AUTOSAR XML (schema 00046)
package /ComponentTypes
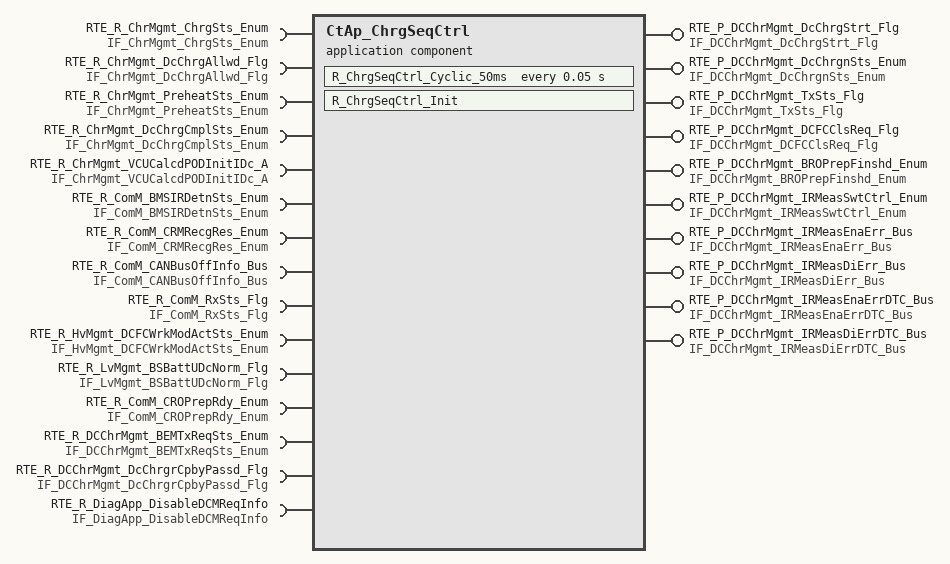
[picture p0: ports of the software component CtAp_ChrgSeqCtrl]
  application sw component type CtAp_ChrgSeqCtrl
    10 x provide port:
      RTE_P_DCChrMgmt_DcChrgStrt_Flg: nonqueued-sender-com-spec{data-element=tec_DCChrMgmt_DcChrgStrt_Flg, init-value=0}, provided-interface=IF_DCChrMgmt_DcChrgStrt_Flg
      RTE_P_DCChrMgmt_DcChrgnSts_Enum: nonqueued-sender-com-spec{data-element=tec_DCChrMgmt_DcChrgnSts_Enum, init-value=0}, provided-interface=IF_DCChrMgmt_DcChrgnSts_Enum
      RTE_P_DCChrMgmt_TxSts_Flg: provided-interface=IF_DCChrMgmt_TxSts_Flg
        provided-com-specs:
          data-element=tec_DCChrMgmt_TxBSDSts_Flg, init-value=0
          data-element=tec_DCChrMgmt_TxBEMSts_Flg, init-value=0
          data-element=tec_DCChrMgmt_TxBSMSts_Flg, init-value=0
          data-element=tec_DCChrMgmt_TxBCSSts_Flg, init-value=0
          data-element=tec_DCChrMgmt_TxBSTSts_Flg, init-value=0
          data-element=tec_DCChrMgmt_TxBCLSts_Flg, init-value=0
          data-element=tec_DCChrMgmt_TxBROSts_Flg, init-value=0
          data-element=tec_DCChrMgmt_TxBCPSts_Flg, init-value=0
          data-element=tec_DCChrMgmt_TxBRMSts_Flg, init-value=0
          data-element=tec_DCChrMgmt_TxBHMSts_Flg, init-value=0
      RTE_P_DCChrMgmt_DCFCClsReq_Flg: nonqueued-sender-com-spec{data-element=tec_DCChrMgmt_DCFCClsReq_Flg, init-value=0}, provided-interface=IF_DCChrMgmt_DCFCClsReq_Flg
      RTE_P_DCChrMgmt_BROPrepFinshd_Enum: nonqueued-sender-com-spec{data-element=tec_DCChrMgmt_BROPrepFinshd_Enum, init-value=0}, provided-interface=IF_DCChrMgmt_BROPrepFinshd_Enum
      RTE_P_DCChrMgmt_IRMeasSwtCtrl_Enum: nonqueued-sender-com-spec{data-element=tec_DCChrMgmt_IRMeasSwtCtrl_Enum, init-value=0}, provided-interface=IF_DCChrMgmt_IRMeasSwtCtrl_Enum
      RTE_P_DCChrMgmt_IRMeasEnaErr_Bus: nonqueued-sender-com-spec{data-element=tec_DCChrMgmt_IRMeasEnaErr_Bus, init-value=fields=[DCChrMgmt_MonStatIRMeasEnaErr:0, DCChrMgmt_MonResIRMeasEnaErr:0, DCChrMgmt_ErrStatIRMeasEnaErr:0, DCChrMgmt_ErrResIRMeasEnaErr:0]}, provided-interface=IF_DCChrMgmt_IRMeasEnaErr_Bus
      RTE_P_DCChrMgmt_IRMeasDiErr_Bus: nonqueued-sender-com-spec{data-element=tec_DCChrMgmt_IRMeasDiErr_Bus, init-value=fields=[DCChrMgmt_MonStatIRMeasDiErr:0, DCChrMgmt_MonResIRMeasDiErr:0, DCChrMgmt_ErrStatIRMeasDiErr:0, DCChrMgmt_ErrResIRMeasDiErr:0]}, provided-interface=IF_DCChrMgmt_IRMeasDiErr_Bus
      RTE_P_DCChrMgmt_IRMeasEnaErrDTC_Bus: nonqueued-sender-com-spec{data-element=tec_DCChrMgmt_IRMeasEnaErrDTC_Bus, init-value=fields=[DCChrMgmt_MonStatIRMeasEnaErrDTC:0, DCChrMgmt_MonResIRMeasEnaErrDTC:0, DCChrMgmt_ErrStatIRMeasEnaErrDTC:0, DCChrMgmt_ErrResIRMeasEnaErrDTC:0]}, provided-interface=IF_DCChrMgmt_IRMeasEnaErrDTC_Bus
      RTE_P_DCChrMgmt_IRMeasDiErrDTC_Bus: nonqueued-sender-com-spec{data-element=tec_DCChrMgmt_IRMeasDiErrDTC_Bus, init-value=fields=[DCChrMgmt_MonStatIRMeasDiErrDTC:0, DCChrMgmt_MonResIRMeasDiErrDTC:0, DCChrMgmt_ErrStatIRMeasDiErrDTC:0, DCChrMgmt_ErrResIRMeasDiErrDTC:0]}, provided-interface=IF_DCChrMgmt_IRMeasDiErrDTC_Bus
    15 x require port:
      RTE_R_ChrMgmt_ChrgSts_Enum: nonqueued-receiver-com-spec{data-element=tec_ChrMgmt_ChrgSts_Enum, filter=data-filter-type=ALWAYS, init-value=0}, required-interface=IF_ChrMgmt_ChrgSts_Enum
      RTE_R_ChrMgmt_DcChrgAllwd_Flg: nonqueued-receiver-com-spec{data-element=tec_ChrMgmt_DcChrgAllwd_Flg, filter=data-filter-type=ALWAYS, init-value=0}, required-interface=IF_ChrMgmt_DcChrgAllwd_Flg
      RTE_R_ChrMgmt_PreheatSts_Enum: nonqueued-receiver-com-spec{data-element=tec_ChrMgmt_PreheatSts_Enum, filter=data-filter-type=ALWAYS, init-value=0}, required-interface=IF_ChrMgmt_PreheatSts_Enum
      RTE_R_ChrMgmt_DcChrgCmplSts_Enum: nonqueued-receiver-com-spec{data-element=tec_ChrMgmt_DcChrgCmplSts_Enum, filter=data-filter-type=ALWAYS, init-value=0}, required-interface=IF_ChrMgmt_DcChrgCmplSts_Enum
      RTE_R_ChrMgmt_VCUCalcdPODInitIDc_A: nonqueued-receiver-com-spec{data-element=tec_ChrMgmt_VCUCalcdPODInitIDc_A, filter=data-filter-type=ALWAYS, init-value=0}, required-interface=IF_ChrMgmt_VCUCalcdPODInitIDc_A
      RTE_R_ComM_BMSIRDetnSts_Enum: nonqueued-receiver-com-spec{data-element=tec_ComM_BMSIRDetnSts_Enum, filter=data-filter-type=ALWAYS, init-value=0}, required-interface=IF_ComM_BMSIRDetnSts_Enum
      RTE_R_ComM_CRMRecgRes_Enum: nonqueued-receiver-com-spec{data-element=tec_ComM_CRMRecgRes_Enum, filter=data-filter-type=ALWAYS, init-value=0}, required-interface=IF_ComM_CRMRecgRes_Enum
      RTE_R_ComM_CANBusOffInfo_Bus: required-interface=IF_ComM_CANBusOffInfo_Bus
        required-com-specs:
          data-element=tec_ComM_EPTCANBusOffInfo_Bus, filter=data-filter-type=ALWAYS, init-value=fields=[ComM_MonStatEPTCANBusOffInfo:0, ComM_MonResEPTCANBusOffInfo:0, ComM_ErrStatEPTCANBusOffInfo:0, ComM_ErrResEPTCANBusOffInfo:0]
          data-element=tec_ComM_CHCANBusOffInfo_Bus, filter=data-filter-type=ALWAYS, init-value=fields=[ComM_MonStatCHCANBusOffInfo:0, ComM_MonResCHCANBusOffInfo:0, ComM_ErrStatCHCANBusOffInfo:0, ComM_ErrResCHCANBusOffInfo:0]
          data-element=tec_ComM_EPTCANBusOffDTCInfo_Bus, filter=data-filter-type=ALWAYS, init-value=fields=[ComM_MonStatEPTCANBusOffDTCInfo:0, ComM_MonResEPTCANBusOffDTCInfo:0, ComM_ErrStatEPTCANBusOffDTCInfo:0, ComM_ErrResEPTCANBusOffDTCInfo:0]
          data-element=tec_ComM_CHCANBusOffDTCInfo_Bus, filter=data-filter-type=ALWAYS, init-value=fields=[ComM_MonStatCHCANBusOffDTCInfo:0, ComM_MonResCHCANBusOffDTCInfo:0, ComM_ErrStatCHCANBusOffDTCInfo:0, ComM_ErrResCHCANBusOffDTCInfo:0]
          data-element=tec_ComM_DCCANBusOffDTCInfo_Bus, init-value=fields=[ComM_MonStatDCCANDTCBusOffInfo:0, ComM_MonResDCCANDTCBusOffInfo:0, ComM_ErrStatDCCANDTCBusOffInfo:0, ComM_ErrResDCCANDTCBusOffInfo:0]
          data-element=tec_ComM_DCCANBusOffInfo_Bus, init-value=fields=[ComM_MonStatDCCANBusOffInfo:0, ComM_MonResDCCANBusOffInfo:0, ComM_ErrStatDCCANBusOffInfo:0, ComM_ErrResDCCANBusOffInfo:0]
      RTE_R_ComM_RxSts_Flg: required-interface=IF_ComM_RxSts_Flg
        required-com-specs:
          data-element=tec_ComM_RxCROSts_Flg, filter=data-filter-type=ALWAYS, init-value=0
          data-element=tec_ComM_RxCEMSts_Flg, filter=data-filter-type=ALWAYS, init-value=0
          data-element=tec_ComM_RxCHMSts_Flg, filter=data-filter-type=ALWAYS, init-value=0
          data-element=tec_ComM_RxCSTSts_Flg, filter=data-filter-type=ALWAYS, init-value=0
          data-element=tec_ComM_RxCSDSts_Flg, filter=data-filter-type=ALWAYS, init-value=0
          data-element=tec_ComM_RxCCSSts_Flg, filter=data-filter-type=ALWAYS, init-value=0
          data-element=tec_ComM_RxCMLSts_Flg, filter=data-filter-type=ALWAYS, init-value=0
          data-element=tec_ComM_RxCRMSts_Flg, filter=data-filter-type=ALWAYS, init-value=0
      RTE_R_HvMgmt_DCFCWrkModActSts_Enum: nonqueued-receiver-com-spec{data-element=tec_HvMgmt_DCFCWrkModActSts_Enum, filter=data-filter-type=ALWAYS, init-value=0}, required-interface=IF_HvMgmt_DCFCWrkModActSts_Enum
      RTE_R_LvMgmt_BSBattUDcNorm_Flg: nonqueued-receiver-com-spec{data-element=tec_LvMgmt_BSBattUDcNorm_Flg, filter=data-filter-type=ALWAYS, init-value=0}, required-interface=IF_LvMgmt_BSBattUDcNorm_Flg
      RTE_R_ComM_CROPrepRdy_Enum: nonqueued-receiver-com-spec{data-element=tec_ComM_CROPrepRdy_Enum, filter=data-filter-type=ALWAYS, init-value=0}, required-interface=IF_ComM_CROPrepRdy_Enum
      RTE_R_DCChrMgmt_BEMTxReqSts_Enum: nonqueued-receiver-com-spec{data-element=tec_DCChrMgmt_BEMTxReqSts_Enum, filter=data-filter-type=ALWAYS, init-value=0}, required-interface=IF_DCChrMgmt_BEMTxReqSts_Enum
      RTE_R_DCChrMgmt_DcChrgrCpbyPassd_Flg: nonqueued-receiver-com-spec{data-element=tec_DCChrMgmt_DcChrgrCpbyPassd_Flg, filter=data-filter-type=ALWAYS, init-value=0}, required-interface=IF_DCChrMgmt_DcChrgrCpbyPassd_Flg
      RTE_R_DiagApp_DisableDCMReqInfo: nonqueued-receiver-com-spec{data-element=tec_DiagApp_DisableDCMReqInfo, filter=data-filter-type=ALWAYS, init-value=0}, required-interface=IF_DiagApp_DisableDCMReqInfo
    behavior CtAp_ChrgSeqCtrl_InternalBehavior
      timing event TMT_R_ChrgSeqCtrl_Cyclic_50ms: start-on-event=R_ChrgSeqCtrl_Cyclic_50ms, period=0.05
      init event CtAp_ChrgSeqCtrl_InitEvent: start-on-event=R_ChrgSeqCtrl_Init
      runnable R_ChrgSeqCtrl_Cyclic_50ms
        data-receive-point-by-arguments:
          22 x access:
            REC_RTE_R_ChrMgmt_ChrgSts_Enum_tec_ChrMgmt_ChrgSts_Enum: accessed-variable=RTE_R_ChrMgmt_ChrgSts_Enum.tec_ChrMgmt_ChrgSts_Enum
            REC_RTE_R_ChrMgmt_DcChrgAllwd_Flg_tec_ChrMgmt_DcChrgAllwd_Flg: accessed-variable=RTE_R_ChrMgmt_DcChrgAllwd_Flg.tec_ChrMgmt_DcChrgAllwd_Flg
            REC_RTE_R_ChrMgmt_DcChrgCmplSts_Enum_tec_ChrMgmt_DcChrgCmplSts_Enum: accessed-variable=RTE_R_ChrMgmt_DcChrgCmplSts_Enum.tec_ChrMgmt_DcChrgCmplSts_Enum
            REC_RTE_R_ChrMgmt_PreheatSts_Enum_tec_ChrMgmt_PreheatSts_Enum: accessed-variable=RTE_R_ChrMgmt_PreheatSts_Enum.tec_ChrMgmt_PreheatSts_Enum
            REC_RTE_R_ChrMgmt_VCUCalcdPODInitIDc_A_tec_ChrMgmt_VCUCalcdPODInitIDc_A: accessed-variable=RTE_R_ChrMgmt_VCUCalcdPODInitIDc_A.tec_ChrMgmt_VCUCalcdPODInitIDc_A
            REC_RTE_R_ComM_BMSIRDetnSts_Enum_tec_ComM_BMSIRDetnSts_Enum: accessed-variable=RTE_R_ComM_BMSIRDetnSts_Enum.tec_ComM_BMSIRDetnSts_Enum
            REC_RTE_R_ComM_CANBusOffInfo_Bus_tec_ComM_EPTCANBusOffInfo_Bus: accessed-variable=RTE_R_ComM_CANBusOffInfo_Bus.tec_ComM_EPTCANBusOffInfo_Bus
            REC_RTE_R_ComM_CRMRecgRes_Enum_tec_ComM_CRMRecgRes_Enum: accessed-variable=RTE_R_ComM_CRMRecgRes_Enum.tec_ComM_CRMRecgRes_Enum
            REC_RTE_R_ComM_CROPrepRdy_Enum_tec_ComM_CROPrepRdy_Enum: accessed-variable=RTE_R_ComM_CROPrepRdy_Enum.tec_ComM_CROPrepRdy_Enum
            REC_RTE_R_ComM_RxSts_Flg_tec_ComM_RxCCSSts_Flg: accessed-variable=RTE_R_ComM_RxSts_Flg.tec_ComM_RxCCSSts_Flg
            REC_RTE_R_ComM_RxSts_Flg_tec_ComM_RxCEMSts_Flg: accessed-variable=RTE_R_ComM_RxSts_Flg.tec_ComM_RxCEMSts_Flg
            REC_RTE_R_ComM_RxSts_Flg_tec_ComM_RxCHMSts_Flg: accessed-variable=RTE_R_ComM_RxSts_Flg.tec_ComM_RxCHMSts_Flg
            REC_RTE_R_ComM_RxSts_Flg_tec_ComM_RxCMLSts_Flg: accessed-variable=RTE_R_ComM_RxSts_Flg.tec_ComM_RxCMLSts_Flg
            REC_RTE_R_ComM_RxSts_Flg_tec_ComM_RxCRMSts_Flg: accessed-variable=RTE_R_ComM_RxSts_Flg.tec_ComM_RxCRMSts_Flg
            REC_RTE_R_ComM_RxSts_Flg_tec_ComM_RxCROSts_Flg: accessed-variable=RTE_R_ComM_RxSts_Flg.tec_ComM_RxCROSts_Flg
            REC_RTE_R_ComM_RxSts_Flg_tec_ComM_RxCSDSts_Flg: accessed-variable=RTE_R_ComM_RxSts_Flg.tec_ComM_RxCSDSts_Flg
            REC_RTE_R_ComM_RxSts_Flg_tec_ComM_RxCSTSts_Flg: accessed-variable=RTE_R_ComM_RxSts_Flg.tec_ComM_RxCSTSts_Flg
            REC_RTE_R_DCChrMgmt_BEMTxReqSts_Enum_tec_DCChrMgmt_BEMTxReqSts_Enum: accessed-variable=RTE_R_DCChrMgmt_BEMTxReqSts_Enum.tec_DCChrMgmt_BEMTxReqSts_Enum
            REC_RTE_R_DCChrMgmt_DcChrgrCpbyPassd_Flg_tec_DCChrMgmt_DcChrgrCpbyPassd_Flg: accessed-variable=RTE_R_DCChrMgmt_DcChrgrCpbyPassd_Flg.tec_DCChrMgmt_DcChrgrCpbyPassd_Flg
            REC_RTE_R_HvMgmt_DCFCWrkModActSts_Enum_tec_HvMgmt_DCFCWrkModActSts_Enum: accessed-variable=RTE_R_HvMgmt_DCFCWrkModActSts_Enum.tec_HvMgmt_DCFCWrkModActSts_Enum
            REC_RTE_R_LvMgmt_BSBattUDcNorm_Flg_tec_LvMgmt_BSBattUDcNorm_Flg: accessed-variable=RTE_R_LvMgmt_BSBattUDcNorm_Flg.tec_LvMgmt_BSBattUDcNorm_Flg
            REC_RTE_R_DiagApp_DisableDCMReqInfo_tec_DiagApp_DisableDCMReqInfo: accessed-variable=RTE_R_DiagApp_DisableDCMReqInfo.tec_DiagApp_DisableDCMReqInfo
        data-send-points:
          19 x access:
            SEND_RTE_P_DCChrMgmt_BROPrepFinshd_Enum_tec_DCChrMgmt_BROPrepFinshd_Enum: accessed-variable=RTE_P_DCChrMgmt_BROPrepFinshd_Enum.tec_DCChrMgmt_BROPrepFinshd_Enum
            SEND_RTE_P_DCChrMgmt_DCFCClsReq_Flg_tec_DCChrMgmt_DCFCClsReq_Flg: accessed-variable=RTE_P_DCChrMgmt_DCFCClsReq_Flg.tec_DCChrMgmt_DCFCClsReq_Flg
            SEND_RTE_P_DCChrMgmt_DcChrgStrt_Flg_tec_DCChrMgmt_DcChrgStrt_Flg: accessed-variable=RTE_P_DCChrMgmt_DcChrgStrt_Flg.tec_DCChrMgmt_DcChrgStrt_Flg
            SEND_RTE_P_DCChrMgmt_DcChrgnSts_Enum_tec_DCChrMgmt_DcChrgnSts_Enum: accessed-variable=RTE_P_DCChrMgmt_DcChrgnSts_Enum.tec_DCChrMgmt_DcChrgnSts_Enum
            SEND_RTE_P_DCChrMgmt_IRMeasDiErrDTC_Bus_tec_DCChrMgmt_IRMeasDiErrDTC_Bus: accessed-variable=RTE_P_DCChrMgmt_IRMeasDiErrDTC_Bus.tec_DCChrMgmt_IRMeasDiErrDTC_Bus
            SEND_RTE_P_DCChrMgmt_IRMeasDiErr_Bus_tec_DCChrMgmt_IRMeasDiErr_Bus: accessed-variable=RTE_P_DCChrMgmt_IRMeasDiErr_Bus.tec_DCChrMgmt_IRMeasDiErr_Bus
            SEND_RTE_P_DCChrMgmt_IRMeasEnaErrDTC_Bus_tec_DCChrMgmt_IRMeasEnaErrDTC_Bus: accessed-variable=RTE_P_DCChrMgmt_IRMeasEnaErrDTC_Bus.tec_DCChrMgmt_IRMeasEnaErrDTC_Bus
            SEND_RTE_P_DCChrMgmt_IRMeasEnaErr_Bus_tec_DCChrMgmt_IRMeasEnaErr_Bus: accessed-variable=RTE_P_DCChrMgmt_IRMeasEnaErr_Bus.tec_DCChrMgmt_IRMeasEnaErr_Bus
            SEND_RTE_P_DCChrMgmt_IRMeasSwtCtrl_Enum_tec_DCChrMgmt_IRMeasSwtCtrl_Enum: accessed-variable=RTE_P_DCChrMgmt_IRMeasSwtCtrl_Enum.tec_DCChrMgmt_IRMeasSwtCtrl_Enum
            SEND_RTE_P_DCChrMgmt_TxSts_Flg_tec_DCChrMgmt_TxBCLSts_Flg: accessed-variable=RTE_P_DCChrMgmt_TxSts_Flg.tec_DCChrMgmt_TxBCLSts_Flg
            SEND_RTE_P_DCChrMgmt_TxSts_Flg_tec_DCChrMgmt_TxBCPSts_Flg: accessed-variable=RTE_P_DCChrMgmt_TxSts_Flg.tec_DCChrMgmt_TxBCPSts_Flg
            SEND_RTE_P_DCChrMgmt_TxSts_Flg_tec_DCChrMgmt_TxBCSSts_Flg: accessed-variable=RTE_P_DCChrMgmt_TxSts_Flg.tec_DCChrMgmt_TxBCSSts_Flg
            SEND_RTE_P_DCChrMgmt_TxSts_Flg_tec_DCChrMgmt_TxBEMSts_Flg: accessed-variable=RTE_P_DCChrMgmt_TxSts_Flg.tec_DCChrMgmt_TxBEMSts_Flg
            SEND_RTE_P_DCChrMgmt_TxSts_Flg_tec_DCChrMgmt_TxBHMSts_Flg: accessed-variable=RTE_P_DCChrMgmt_TxSts_Flg.tec_DCChrMgmt_TxBHMSts_Flg
            SEND_RTE_P_DCChrMgmt_TxSts_Flg_tec_DCChrMgmt_TxBRMSts_Flg: accessed-variable=RTE_P_DCChrMgmt_TxSts_Flg.tec_DCChrMgmt_TxBRMSts_Flg
            SEND_RTE_P_DCChrMgmt_TxSts_Flg_tec_DCChrMgmt_TxBROSts_Flg: accessed-variable=RTE_P_DCChrMgmt_TxSts_Flg.tec_DCChrMgmt_TxBROSts_Flg
            SEND_RTE_P_DCChrMgmt_TxSts_Flg_tec_DCChrMgmt_TxBSDSts_Flg: accessed-variable=RTE_P_DCChrMgmt_TxSts_Flg.tec_DCChrMgmt_TxBSDSts_Flg
            SEND_RTE_P_DCChrMgmt_TxSts_Flg_tec_DCChrMgmt_TxBSMSts_Flg: accessed-variable=RTE_P_DCChrMgmt_TxSts_Flg.tec_DCChrMgmt_TxBSMSts_Flg
            SEND_RTE_P_DCChrMgmt_TxSts_Flg_tec_DCChrMgmt_TxBSTSts_Flg: accessed-variable=RTE_P_DCChrMgmt_TxSts_Flg.tec_DCChrMgmt_TxBSTSts_Flg
      runnable R_ChrgSeqCtrl_Init
  swc implementation CtAp_ChrgSeqCtrl_Implementation: behavior=CtAp_ChrgSeqCtrl_InternalBehavior
